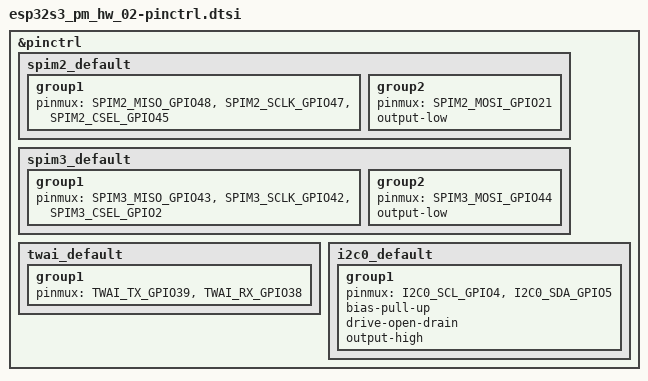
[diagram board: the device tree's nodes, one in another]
/*
 * Copyright (c) 2025 Pavel Maloletkov
 *
 * SPDX-License-Identifier: Apache-2.0
 */

#include <zephyr/dt-bindings/pinctrl/esp-pinctrl-common.h>
#include <dt-bindings/pinctrl/esp32s3-pinctrl.h>
#include <zephyr/dt-bindings/pinctrl/esp32s3-gpio-sigmap.h>

&pinctrl {
	spim2_default: spim2_default {
		group1 {
			pinmux = <SPIM2_MISO_GPIO48>,
					 <SPIM2_SCLK_GPIO47>,
					 <SPIM2_CSEL_GPIO45>;
		};

		group2 {
			pinmux = <SPIM2_MOSI_GPIO21>;
			output-low;
		};
	};

	spim3_default: spim3_default {
		group1 {
			pinmux = <SPIM3_MISO_GPIO43>,
					 <SPIM3_SCLK_GPIO42>,
					 <SPIM3_CSEL_GPIO2>;
		};

		group2 {
			pinmux = <SPIM3_MOSI_GPIO44>;
			output-low;
		};
	};

	twai_default: twai_default {
		group1 {
			pinmux = <TWAI_TX_GPIO39>,
					 <TWAI_RX_GPIO38>;
		};
	};

	i2c0_default: i2c0_default {
		group1 {
			pinmux = <I2C0_SCL_GPIO4>,
				 	 <I2C0_SDA_GPIO5>;
			bias-pull-up;
			drive-open-drain;
			output-high;
		};
	};
};
